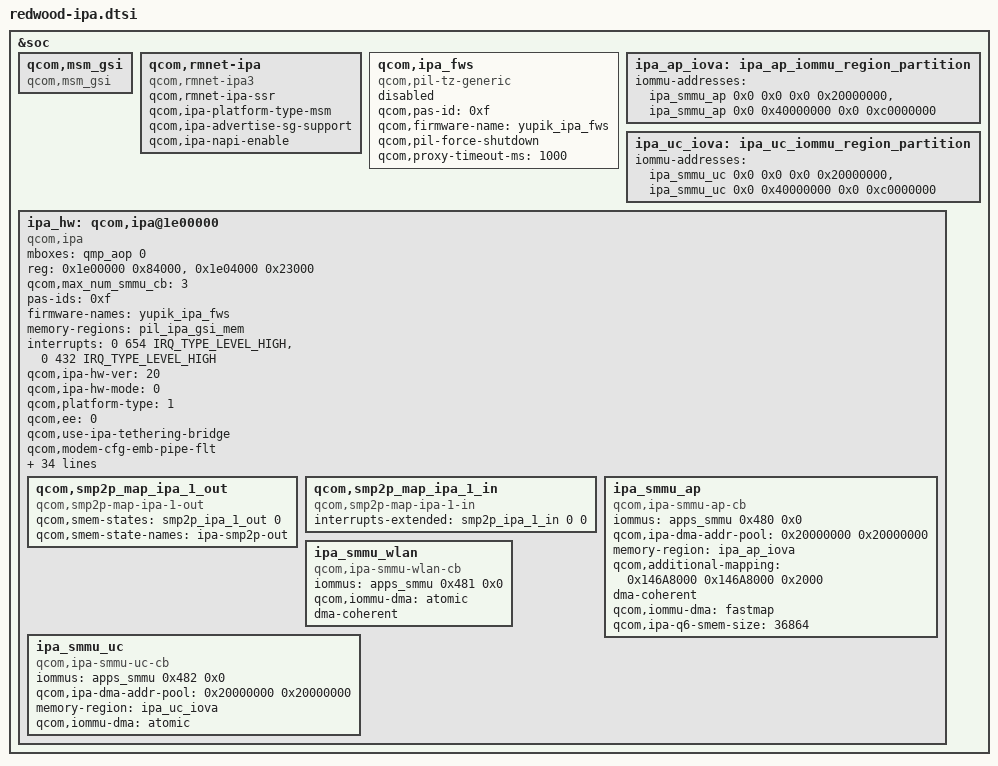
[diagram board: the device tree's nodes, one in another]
// SPDX-License-Identifier: BSD-3-Clause
/*
 * IPA v4.11 for mobile data, from the 5.4 yupik device tree; 6.12 has no IPA
 * nodes for Yupik. The 11ad context bank is left out: redwood has no 11ad.
 */

#include <dt-bindings/clock/qcom,rpmh.h>
#include <dt-bindings/interconnect/qcom,yupik.h>
#include <dt-bindings/interrupt-controller/arm-gic.h>

&soc {
	qcom,msm_gsi {
		compatible = "qcom,msm_gsi";
	};

	qcom,rmnet-ipa {
		compatible = "qcom,rmnet-ipa3";
		qcom,rmnet-ipa-ssr;
		qcom,ipa-platform-type-msm;
		qcom,ipa-advertise-sg-support;
		qcom,ipa-napi-enable;
	};

	qcom,ipa_fws {
		compatible = "qcom,pil-tz-generic";
		qcom,pas-id = <0xf>;
		qcom,firmware-name = "yupik_ipa_fws";
		qcom,pil-force-shutdown;
		qcom,proxy-timeout-ms = <1000>;
		status = "disabled";
	};

	/*
	 * 6.12 dropped qcom,iommu-dma-addr-pool, and without an IOVA window
	 * the AP and uC context banks get no IOMMU domain. Reserve everything
	 * around the 512M window at 0x20000000 the 5.4 pool gave them; the
	 * driver reads the window itself from qcom,ipa-dma-addr-pool.
	 */
	ipa_ap_iova: ipa_ap_iommu_region_partition {
		iommu-addresses = <&ipa_smmu_ap 0x0 0x0 0x0 0x20000000>,
				  <&ipa_smmu_ap 0x0 0x40000000 0x0 0xc0000000>;
	};

	ipa_uc_iova: ipa_uc_iommu_region_partition {
		iommu-addresses = <&ipa_smmu_uc 0x0 0x0 0x0 0x20000000>,
				  <&ipa_smmu_uc 0x0 0x40000000 0x0 0xc0000000>;
	};

	ipa_hw: qcom,ipa@1e00000 {
		compatible = "qcom,ipa";
		mboxes = <&qmp_aop 0>;
		reg =
			<0x1e00000 0x84000>,
			<0x1e04000 0x23000>;
		reg-names = "ipa-base", "gsi-base";
		qcom,max_num_smmu_cb = <3>;
		pas-ids = <0xf>;
		firmware-names = "yupik_ipa_fws";
		memory-regions = <&pil_ipa_gsi_mem>;
		interrupts =
			<0 654 IRQ_TYPE_LEVEL_HIGH>,
			<0 432 IRQ_TYPE_LEVEL_HIGH>;
		interrupt-names = "ipa-irq", "gsi-irq";
		qcom,ipa-hw-ver = <20>; /* IPA core version = IPAv4.11 */
		qcom,ipa-hw-mode = <0>;
		qcom,platform-type = <1>; /* MSM platform */
		qcom,ee = <0>;
		qcom,use-ipa-tethering-bridge;
		qcom,modem-cfg-emb-pipe-flt;
		qcom,ipa-wdi3-over-gsi;
		qcom,arm-smmu;
		qcom,smmu-fast-map;
		qcom,use-64-bit-dma-mask;
		qcom,ipa-endp-delay-wa-v2;
		qcom,eth-bridging-not-supported;
		qcom,bw-monitor-supported;
		qcom,lan-rx-napi;
		qcom,tx-napi;
		qcom,rmnet-ctl-enable;
		qcom,use-gsi-ipa-fw = "yupik_ipa_fws";
		qcom,tx-wrapper-cache-max-size = <400>;
		qcom,ipa-gpi-event-rp-ddr;
		clock-names = "core_clk";
		clocks = <&rpmhcc RPMH_IPA_CLK>;
		qcom,interconnect,num-cases = <5>;
		qcom,interconnect,num-paths = <3>;
		interconnects = <&aggre2_noc MASTER_IPA &gem_noc SLAVE_LLCC>,
			<&mc_virt MASTER_LLCC &mc_virt SLAVE_EBI1>,
			<&gem_noc MASTER_APPSS_PROC &cnoc2 SLAVE_IPA_CFG>;
		interconnect-names = "ipa_to_llcc", "llcc_to_ebi1", "appss_to_ipa";
		/* No vote */
		qcom,no-vote =
		<0 0 0 0 0 0>;

		/* SVS2 */
		qcom,svs2 =
		<150000 600000 150000 1804000 0 74000>;

		/* SVS */
		qcom,svs =
		<625000 1200000 625000 3072000 0 150000>;

		/* NOMINAL */
		qcom,nominal =
		<1250000 2400000 1250000 6220800 0 400000>;

		/* TURBO */
		qcom,turbo =
		<2000000 3500000 2000000 7219200 0 400000>;

		qcom,bus-vector-names = "MIN", "SVS2", "SVS", "NOMINAL",
			"TURBO";
		qcom,throughput-threshold = <600 2500 5000>;
		qcom,scaling-exceptions = <>;

		/* smp2p information */
		qcom,smp2p_map_ipa_1_out {
			compatible = "qcom,smp2p-map-ipa-1-out";
			qcom,smem-states = <&smp2p_ipa_1_out 0>;
			qcom,smem-state-names = "ipa-smp2p-out";
		};

		qcom,smp2p_map_ipa_1_in {
			compatible = "qcom,smp2p-map-ipa-1-in";
			interrupts-extended = <&smp2p_ipa_1_in 0 0>;
			interrupt-names = "ipa-smp2p-in";
		};

		ipa_smmu_ap: ipa_smmu_ap {
			compatible = "qcom,ipa-smmu-ap-cb";
			iommus = <&apps_smmu 0x480 0x0>;
			qcom,ipa-dma-addr-pool = <0x20000000 0x20000000>;
			memory-region = <&ipa_ap_iova>;
			qcom,additional-mapping =
				/* modem tables in IMEM */
				<0x146A8000 0x146A8000 0x2000>;
			dma-coherent;
			qcom,iommu-dma = "fastmap";
			qcom,ipa-q6-smem-size = <36864>;
		};

		ipa_smmu_wlan: ipa_smmu_wlan {
			compatible = "qcom,ipa-smmu-wlan-cb";
			iommus = <&apps_smmu 0x481 0x0>;
			qcom,iommu-dma = "atomic";
			dma-coherent;
		};

		ipa_smmu_uc: ipa_smmu_uc {
			compatible = "qcom,ipa-smmu-uc-cb";
			iommus = <&apps_smmu 0x482 0x0>;
			qcom,ipa-dma-addr-pool = <0x20000000 0x20000000>;
			memory-region = <&ipa_uc_iova>;
			qcom,iommu-dma = "atomic";
		};

	};
};
